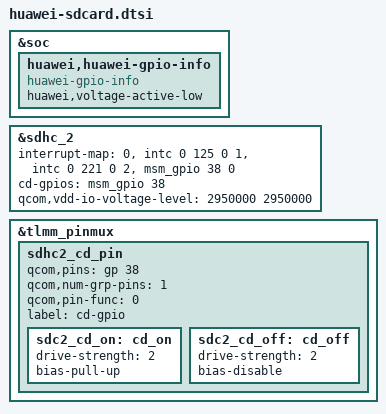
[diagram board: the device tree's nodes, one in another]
/* < DTS2015072404956 goupeipei 20150724 begin */
/* < DTS2014111105643 luchao 20141111 begin */
&soc {
        huawei,huawei-gpio-info {
                compatible = "huawei-gpio-info";
                huawei,voltage-active-low;
        };
     };
/* DTS2014111105643 luchao 20141111 end > */
/* < DTS2014121206768 luchao 20141212 begin */
/* < DTS2015020306974 luchao 20150203 begin */
&sdhc_2 {
	interrupt-map = <0 &intc 0 125 0
		1 &intc 0 221 0
		2 &msm_gpio 38 0>;
	cd-gpios = <&msm_gpio 38 0x0>;
	qcom,vdd-io-voltage-level = <2950000 2950000>;
	/* < DTS2015100903237  zengwei 20151009 begin */
	/* revert DTS2015062603195,pick DTS2015031302205. use deferred resume*/
	/* DTS2015100903237  zengwei 20151009 end > */

};
/* DTS2015020306974 luchao 20150203 end > */
/* DTS2014121206768 luchao 20141212 end > */
/* < DTS2015010408131 luchao 20150104 begin */
&tlmm_pinmux {
	sdhc2_cd_pin {
		qcom,pins = <&gp 38>;
		qcom,num-grp-pins = <1>;
		qcom,pin-func = <0>;
		label = "cd-gpio";
		sdc2_cd_on: cd_on {
			drive-strength = <2>;
			bias-pull-up;
		};
		sdc2_cd_off: cd_off {
			drive-strength = <2>;
			bias-disable;
		};
	};
};
/* DTS2015010408131 luchao 20150104 end > */
/* DTS2015072404956 goupeipei 20150724 end > */
